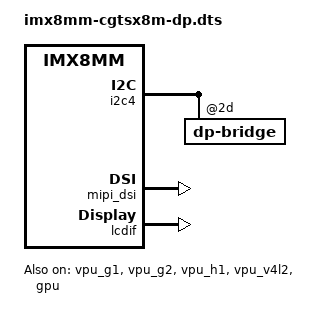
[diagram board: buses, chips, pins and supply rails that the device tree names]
// SPDX-License-Identifier: (GPL-2.0+ OR MIT)
/*
 * Copyright (C) 2025 congatec GmbH
 * Author: Lukas Posadka <lukas.posadka@congatec.com>
 */

/dts-v1/;

#include "imx8mm-cgtsx8m.dts"

&i2c4 {
	dp-bridge@2d {
		status = "okay";
	};
};

&mipi_dsi {
	status = "okay";
};

&lcdif {
	status = "okay";
};

&vpu_g1 {
	status = "okay";
};

&vpu_g2 {
	status = "okay";
};

&vpu_h1 {
	status = "okay";
};

&vpu_v4l2 {
	status = "okay";
};

&gpu {
	status = "okay";
};
